# CY8C4245AXI_483 register map
File version: 0.1
PSoC 4200
Registers are 32-bit, read-write, no defined reset value unless marked. A register's access mark holds for its fields unless they carry their own. Offsets are from the block's base; lines under a group give offsets from that group; [hi:lo] are bit positions; {n}, {i} and the like mark numbered series; 'fields as' and 'values as' point back to an identical list; <NAME> marks a mode.

## Memory map
0x40060000 I2CS size 0xFCD — Serial Communication Block
0x400F0000 Counter_1 size 0x92
0x400F0022 PWM size 0x72
0x400F0071 Control_Reg size 0x1

## PWM
Base 0x400F0022
0x00 PWM_COMPARE_Reg 16-bit — UDB.D0 - Assigned Compare Value
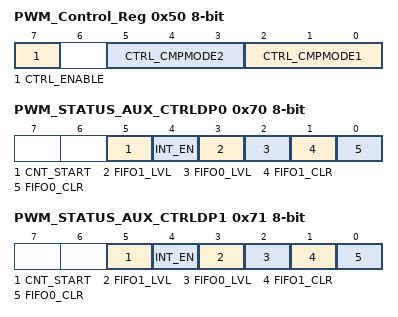
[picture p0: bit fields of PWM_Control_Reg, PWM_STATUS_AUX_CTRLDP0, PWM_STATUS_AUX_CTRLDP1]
0x50 PWM_Control_Reg 8-bit — UDB Control Register - Assigned Control Register Value
  [7] CTRL_ENABLE — Enable the PWM
  [5:3] CTRL_CMPMODE2 — Compare mode 2
  [2:0] CTRL_CMPMODE1 — Compare mode 1
0x70 PWM_STATUS_AUX_CTRLDP0 8-bit — UDB Auxilliary Control Register
  [5] CNT_START — FIFO0 clear
    0=E_CNT_START0 (Disable counter); 1=E_CNT_START1 (Enable counter)
  [4] INT_EN
    0=E_INT_EN0 (Interrupt disabled); 1=E_INT_EN1 (Interrupt enabled)
  [3] FIFO1_LVL — FIFO level
    0=E_FIFO_LVL_0 (FIFO LVL: input mode: FIFO not full; output mode: FIFO not empty); 1=E_FIFO_LVL_1 (FIFO LVL: input mode: FIFO at least 1/2 empty; output mode: FIFO at least 1/2 full)
  [2] FIFO0_LVL — FIFO level
    values as FIFO1_LVL
  [1] FIFO1_CLR — FIFO1 clear
    0=E_FIFO_CLR_0 (Normal FIFO operation); 1=E_FIFO_CLR_1 (Clear FIFO state)
  [0] FIFO0_CLR — FIFO0 clear
    values as FIFO1_CLR
0x71 PWM_STATUS_AUX_CTRLDP1 8-bit — UDB Auxilliary Control Register
  fields as PWM_STATUS_AUX_CTRLDP0

## Control_Reg
Base 0x400F0071
0x00 Control_Reg_CONTROL_REG 8-bit

## Counter_1
Base 0x400F0000
0x00 Counter_1_COUNTER 16-bit — UDB.A0 - Current Counter Value
0x20 Counter_1_PERIOD 16-bit — UDB.D0 - Assigned Period
0x30 Counter_1_COMPARE 16-bit — UDB.D1 - Assigned Compare Value
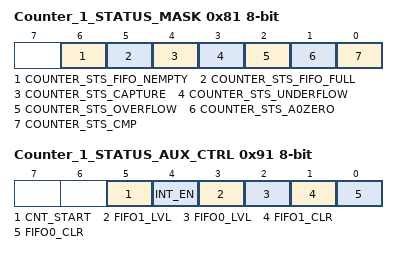
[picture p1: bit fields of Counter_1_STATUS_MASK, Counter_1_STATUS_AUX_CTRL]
0x81 Counter_1_STATUS_MASK 8-bit — UDB Status bits Interrupt Mask Enable Register
  [6] COUNTER_STS_FIFO_NEMPTY — FIFO Not Empty Status
  [5] COUNTER_STS_FIFO_FULL — FIFO Full Status
  [4] COUNTER_STS_CAPTURE — Capture Status
  [3] COUNTER_STS_UNDERFLOW — Underflow status
  [2] COUNTER_STS_OVERFLOW — Overflow status
  [1] COUNTER_STS_A0ZERO — A0 Zero ouput status
  [0] COUNTER_STS_CMP — Compare output status
0x91 Counter_1_STATUS_AUX_CTRL 8-bit — UDB Auxilliary Control Register
  [5] CNT_START — FIFO0 clear
    0=E_CNT_START0 (Disable counter); 1=E_CNT_START1 (Enable counter)
  [4] INT_EN
    0=E_INT_EN0 (Interrupt disabled); 1=E_INT_EN1 (Interrupt enabled)
  [3] FIFO1_LVL — FIFO level
    0=E_FIFO_LVL_0 (FIFO LVL: input mode: FIFO not full; output mode: FIFO not empty); 1=E_FIFO_LVL_1 (FIFO LVL: input mode: FIFO at least 1/2 empty; output mode: FIFO at least 1/2 full)
  [2] FIFO0_LVL — FIFO level
    values as FIFO1_LVL
  [1] FIFO1_CLR — FIFO1 clear
    0=E_FIFO_CLR_0 (Normal FIFO operation); 1=E_FIFO_CLR_1 (Clear FIFO state)
  [0] FIFO0_CLR — FIFO0 clear
    values as FIFO1_CLR
